AUTOSAR XML (schema 4.0)
standard types defined: float32, float64, sint16, sint32, sint8, uint16, uint32, uint8, void, boolean
package /ImplDataTypes
  7 x impl type, all with category=TYPE_REFERENCE, type-emitter=RTE:
    IoPositionSensorReadingType: implementation-data-type=uint8
    IoWeightSensorReadingType: implementation-data-type=uint16
    MultiStateBtn: implementation-data-type=uint8
    SeatModeBtnType: implementation-data-type=uint8
    SensorPositionType: implementation-data-type=uint8
    SensorWeightType: implementation-data-type=uint8
    StepMotorStepType: implementation-data-type=uint8
package /MappingSets
  data type mapping set MappingSet: mode-request-type-map{implementation-data-type=uint8, mode-group=SeatCtrlMode}
package /PortInterfaces/ClientServer
  6 x client server interface:
    CsIf_IoGetSensorPosition
      operation IoGet
        arg position: type=IoPositionSensorReadingType, direction=OUT
    CsIf_IoGetSensorWeight
      operation IoGet
        arg weight: type=IoWeightSensorReadingType, direction=OUT
    CsIf_IoSetMotor
      operation IoSetForward
      operation IoSetReverse
    CsIf_PositionSensor
      operation GetPosition
        arg position: type=SensorPositionType, direction=OUT
    CsIf_StepMotor
      operation Move
        arg step: type=StepMotorStepType, direction=IN
    CsIf_WeightSensor
      operation GetWeight
        arg weight: type=SensorWeightType, direction=OUT
package /PortInterfaces/ModeSwitch
  mode switch interface MsIf_SeatCtrlMode
    mode group SeatCtrlMode: type=SeatCtrlMode
  mode declaration group SeatCtrlMode: category=ALPHABETIC_ORDER, initial-mode=INIT, on-transition-value=255
    mode AUTO
    mode INIT
    mode MANUAL
package /PortInterfaces/SenderReceiver
  sender receiver interface SrIf_SeatCntlData
    data Height: type=uint8
    data Incline: type=uint8
    data Slide: type=uint8
  sender receiver interface SrIf_SeatCtrlBtns
    data HeightBtnState: type=MultiStateBtn
    data InclineBtnState: type=MultiStateBtn
    data SlideBtnState: type=MultiStateBtn
  sender receiver interface SrIf_SeatModeBtn
    data SeatModeBtn: type=SeatModeBtnType
package /SoftwareComponents
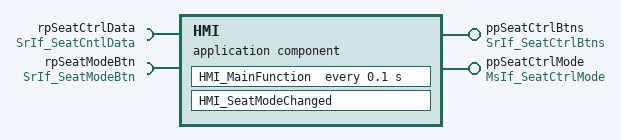
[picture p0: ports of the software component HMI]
  application sw component type HMI
    provide port ppSeatCtrlBtns: provided-interface=SrIf_SeatCtrlBtns
    provide port ppSeatCtrlMode: provided-interface=MsIf_SeatCtrlMode
    require port rpSeatCtrlData: required-interface=SrIf_SeatCntlData
    require port rpSeatModeBtn: required-interface=SrIf_SeatModeBtn
    behavior Ibhv_HMI: data-type-mapping=MappingSet, handle-termination-and-restart=NO-SUPPORT
      data received event DRE_rpSeatModeBtn_SeatModeBtn: start-on-event=HMI_SeatModeChanged, data=rpSeatModeBtn.SeatModeBtn
      timing event TE_HMI_MainFunction_100ms: start-on-event=HMI_MainFunction, period=0.1
      runnable HMI_MainFunction
        data-receive-point-by-arguments:
          access DRP_rpSeatCtrlData_Height: accessed-variable=rpSeatCtrlData.Height
          access DRP_rpSeatCtrlData_Incline: accessed-variable=rpSeatCtrlData.Incline
          access DRP_rpSeatCtrlData_Slide: accessed-variable=rpSeatCtrlData.Slide
        data-send-points:
          access DSP_ppSeatCtrlBtns_HeightBtnState: accessed-variable=ppSeatCtrlBtns.HeightBtnState
          access DSP_ppSeatCtrlBtns_InclineBtnState: accessed-variable=ppSeatCtrlBtns.InclineBtnState
          access DSP_ppSeatCtrlBtns_SlideBtnState: accessed-variable=ppSeatCtrlBtns.SlideBtnState
      runnable HMI_SeatModeChanged
        data-receive-point-by-arguments:
          access DRP_rpSeatModeBtn_SeatModeBtn: accessed-variable=rpSeatModeBtn.SeatModeBtn
        mode switch point MSP_ppSeatCtrlMode_ppSeatCtrlMode: mode-group=ppSeatCtrlMode.SeatCtrlMode
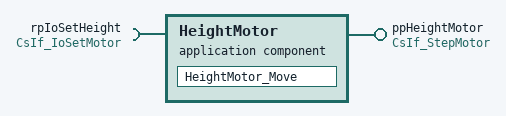
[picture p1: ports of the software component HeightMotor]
  application sw component type HeightMotor
    provide port ppHeightMotor: provided-interface=CsIf_StepMotor
    require port rpIoSetHeight: required-interface=CsIf_IoSetMotor
    behavior Ibhv_HeightMotor: data-type-mapping=MappingSet, handle-termination-and-restart=NO-SUPPORT
      operation invoked event OIE_ppHeightMotor_Move: start-on-event=HeightMotor_Move, operation=ppHeightMotor.Move
      runnable HeightMotor_Move
        sync call SCP_rpIoSetHeight_IoSetForward: operation=rpIoSetHeight.IoSetForward, timeout=0.0
        sync call SCP_rpIoSetHeight_IoSetReverse: operation=rpIoSetHeight.IoSetReverse, timeout=0.0
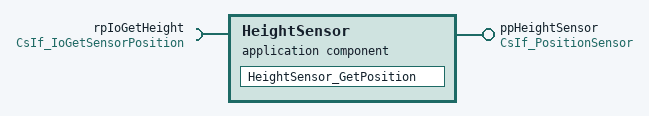
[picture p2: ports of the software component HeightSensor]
  application sw component type HeightSensor
    provide port ppHeightSensor: provided-interface=CsIf_PositionSensor
    require port rpIoGetHeight: required-interface=CsIf_IoGetSensorPosition
    behavior Ibhv_HeightSensor: data-type-mapping=MappingSet, handle-termination-and-restart=NO-SUPPORT
      operation invoked event OIE_ppHeightSensor_GetPosition: start-on-event=HeightSensor_GetPosition, operation=ppHeightSensor.GetPosition
      runnable HeightSensor_GetPosition
        sync call SCP_rpIoGetHeight_IoGet: operation=rpIoGetHeight.IoGet, timeout=0.0
  10 x swc implementation, all with programming-language=C, sw-version=1.0.0, vendor-id=255:
    Impl_HMI: behavior=Ibhv_HMI
      code-descriptors:
        code Code: artifact-descriptors=autosar-engineering-object={short-label=SWC.c, category=SWSRC}
      resource consumption ResourceConsumption
    Impl_HeightMotor: behavior=Ibhv_HeightMotor
      code-descriptors:
        code Code: artifact-descriptors=autosar-engineering-object={short-label=SWC.c, category=SWSRC}
      resource consumption ResourceConsumption
    Impl_HeightSensor: behavior=Ibhv_HeightSensor
      code-descriptors:
        code Code: artifact-descriptors=autosar-engineering-object={short-label=SWC.c, category=SWSRC}
      resource consumption ResourceConsumption
    Impl_InclineMotor: behavior=Ibhv_InclineMotor
      code-descriptors:
        code Code: artifact-descriptors=autosar-engineering-object={short-label=SWC.c, category=SWSRC}
      resource consumption ResourceConsumption
    Impl_InclineSensor: behavior=Ibhv_InclineSensor
      code-descriptors:
        code Code: artifact-descriptors=autosar-engineering-object={short-label=SWC.c, category=SWSRC}
      resource consumption ResourceConsumption
    Impl_IoHwAbs: behavior=Ibhv_IoHwAbs
      code-descriptors:
        code Code: artifact-descriptors=autosar-engineering-object={short-label=SWC.c, category=SWSRC}
      resource consumption ResourceConsumption
    Impl_SeatMrg: behavior=Ibhv_SeatMrg
      code-descriptors:
        code Code: artifact-descriptors=autosar-engineering-object={short-label=SWC.c, category=SWSRC}
      resource consumption ResourceConsumption
    Impl_SideSensor: behavior=Ibhv_SideSensor
      code-descriptors:
        code Code: artifact-descriptors=autosar-engineering-object={short-label=SWC.c, category=SWSRC}
      resource consumption ResourceConsumption
    Impl_SlideMotor: behavior=Ibhv_SlideMotor
      code-descriptors:
        code Code: artifact-descriptors=autosar-engineering-object={short-label=SWC.c, category=SWSRC}
      resource consumption ResourceConsumption
    Impl_WeightSensor: behavior=Ibhv_WeightSensor
      code-descriptors:
        code Code: artifact-descriptors=autosar-engineering-object={short-label=SWC.c, category=SWSRC}
      resource consumption ResourceConsumption
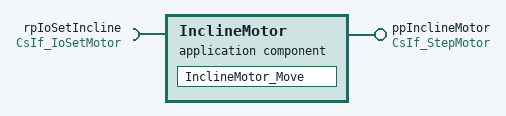
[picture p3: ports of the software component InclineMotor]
  application sw component type InclineMotor
    provide port ppInclineMotor: provided-interface=CsIf_StepMotor
    require port rpIoSetIncline: required-interface=CsIf_IoSetMotor
    behavior Ibhv_InclineMotor: data-type-mapping=MappingSet, handle-termination-and-restart=NO-SUPPORT
      operation invoked event OIE_ppInclineMotor_Move: start-on-event=InclineMotor_Move, operation=ppInclineMotor.Move
      runnable InclineMotor_Move
        sync call SCP_rpIoSetIncline_IoSetForward: operation=rpIoSetIncline.IoSetForward, timeout=0.0
        sync call SCP_rpIoSetIncline_IoSetReverse: operation=rpIoSetIncline.IoSetReverse, timeout=0.0
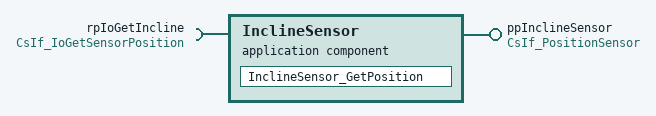
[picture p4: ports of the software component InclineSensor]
  application sw component type InclineSensor
    provide port ppInclineSensor: provided-interface=CsIf_PositionSensor
    require port rpIoGetIncline: required-interface=CsIf_IoGetSensorPosition
    behavior Ibhv_InclineSensor: data-type-mapping=MappingSet, handle-termination-and-restart=NO-SUPPORT
      operation invoked event OIE_ppInclineSensor_GetPosition: start-on-event=InclineSensor_GetPosition, operation=ppInclineSensor.GetPosition
      runnable InclineSensor_GetPosition
        sync call SCP_rpIoGetIncline_IoGet: operation=rpIoGetIncline.IoGet, timeout=0.0
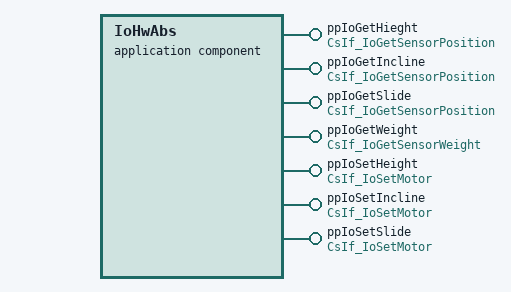
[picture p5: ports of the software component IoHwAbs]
  application sw component type IoHwAbs
    7 x provide port:
      ppIoGetHieght: provided-interface=CsIf_IoGetSensorPosition
      ppIoGetIncline: provided-interface=CsIf_IoGetSensorPosition
      ppIoGetSlide: provided-interface=CsIf_IoGetSensorPosition
      ppIoGetWeight: provided-interface=CsIf_IoGetSensorWeight
      ppIoSetHeight: provided-interface=CsIf_IoSetMotor
      ppIoSetIncline: provided-interface=CsIf_IoSetMotor
      ppIoSetSlide: provided-interface=CsIf_IoSetMotor
    behavior Ibhv_IoHwAbs: data-type-mapping=MappingSet, handle-termination-and-restart=NO-SUPPORT
      10 x operation invoked event:
        OIE_ppIoGetHieght_IoGet: start-on-event=IoHwAbs_ECUGet_Height, operation=ppIoGetHieght.IoGet
        OIE_ppIoGetIncline_IoGet: start-on-event=IoHwAbs_ECUGet_Incline, operation=ppIoGetIncline.IoGet
        OIE_ppIoGetSlide_IoGet: start-on-event=IoHwAbs_ECUGet_Slide, operation=ppIoGetSlide.IoGet
        OIE_ppIoGetWeight_IoGet: start-on-event=IoHwAbs_ECUGet_Weight, operation=ppIoGetWeight.IoGet
        OIE_ppIoSetHeight_IoSetForward: start-on-event=IoHwAbs_ECUSetForward_Height, operation=ppIoSetHeight.IoSetForward
        OIE_ppIoSetHeight_IoSetReverse: start-on-event=IoHwAbs_ECUSetReverse_Height, operation=ppIoSetHeight.IoSetReverse
        OIE_ppIoSetIncline_IoSetForward: start-on-event=IoHwAbs_ECUSetForward_Incline, operation=ppIoSetIncline.IoSetForward
        OIE_ppIoSetIncline_IoSetReverse: start-on-event=IoHwAbs_ECUSetReverse_Incline, operation=ppIoSetIncline.IoSetReverse
        OIE_ppIoSetSlide_IoSetForward: start-on-event=IoHwAbs_ECUSetForward_Slide, operation=ppIoSetSlide.IoSetForward
        OIE_ppIoSetSlide_IoSetReverse: start-on-event=IoHwAbs_ECUSetReverse_Slide, operation=ppIoSetSlide.IoSetReverse
      10 x runnable:
        IoHwAbs_ECUGet_Height
        IoHwAbs_ECUGet_Incline
        IoHwAbs_ECUGet_Slide
        IoHwAbs_ECUGet_Weight
        IoHwAbs_ECUSetForward_Height
        IoHwAbs_ECUSetForward_Incline
        IoHwAbs_ECUSetForward_Slide
        IoHwAbs_ECUSetReverse_Height
        IoHwAbs_ECUSetReverse_Incline
        IoHwAbs_ECUSetReverse_Slide
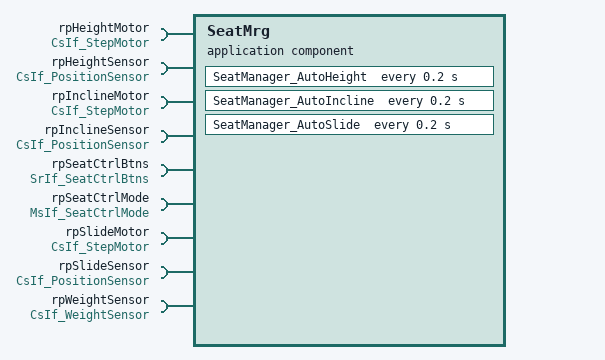
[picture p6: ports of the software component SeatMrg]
  application sw component type SeatMrg
    9 x require port:
      rpHeightMotor: required-interface=CsIf_StepMotor
      rpHeightSensor: required-interface=CsIf_PositionSensor
      rpInclineMotor: required-interface=CsIf_StepMotor
      rpInclineSensor: required-interface=CsIf_PositionSensor
      rpSeatCtrlBtns: required-interface=SrIf_SeatCtrlBtns
      rpSeatCtrlMode: required-interface=MsIf_SeatCtrlMode
      rpSlideMotor: required-interface=CsIf_StepMotor
      rpSlideSensor: required-interface=CsIf_PositionSensor
      rpWeightSensor: required-interface=CsIf_WeightSensor
    behavior Ibhv_SeatMrg: data-type-mapping=MappingSet, handle-termination-and-restart=NO-SUPPORT
      data received event DRE_rpSeatCtrlBtns_HeightBtnState: start-on-event=SeatManager_SetHeight, data=rpSeatCtrlBtns.HeightBtnState
      data received event DRE_rpSeatCtrlBtns_InclineBtnState: start-on-event=SeatManager_SetIncline, data=rpSeatCtrlBtns.InclineBtnState
      data received event DRE_rpSeatCtrlBtns_SlideBtnState: start-on-event=SeatManager_SetSlide, data=rpSeatCtrlBtns.SlideBtnState
      timing event TE_SeatManager_AutoHeight_200ms: start-on-event=SeatManager_AutoHeight, period=0.2
      timing event TE_SeatManager_AutoIncline_200ms: start-on-event=SeatManager_AutoIncline, period=0.2
      timing event TE_SeatManager_AutoSlide_200ms: start-on-event=SeatManager_AutoSlide, period=0.2
      6 x runnable:
        SeatManager_AutoHeight
          sync call SCP_rpHeightMotor_Move: operation=rpHeightMotor.Move, timeout=0.0
          sync call SCP_rpHeightSensor_GetPosition: operation=rpHeightSensor.GetPosition, timeout=0.0
          sync call SCP_rpWeightSensor_GetWeight: operation=rpWeightSensor.GetWeight, timeout=0.0
        SeatManager_AutoIncline
          sync call SCP_rpInclineMotor_Move: operation=rpInclineMotor.Move, timeout=0.0
          sync call SCP_rpInclineSensor_GetPosition: operation=rpInclineSensor.GetPosition, timeout=0.0
          sync call SCP_rpWeightSensor_GetWeight: operation=rpWeightSensor.GetWeight, timeout=0.0
        SeatManager_AutoSlide
          sync call SCP_rpSlideMotor_Move: operation=rpSlideMotor.Move, timeout=0.0
          sync call SCP_rpSlideSensor_GetPosition: operation=rpSlideSensor.GetPosition, timeout=0.0
          sync call SCP_rpWeightSensor_GetWeight: operation=rpWeightSensor.GetWeight, timeout=0.0
        SeatManager_SetHeight
          data-receive-point-by-arguments:
            access DRP_rpSeatCtrlBtns_HeightBtnState: accessed-variable=rpSeatCtrlBtns.HeightBtnState
          sync call SCP_rpHeightMotor_Move: operation=rpHeightMotor.Move, timeout=0.0
        SeatManager_SetIncline
          data-receive-point-by-arguments:
            access DRP_rpSeatCtrlBtns_InclineBtnState: accessed-variable=rpSeatCtrlBtns.InclineBtnState
          sync call SCP_rpSlideMotor_Move: operation=rpSlideMotor.Move, timeout=0.0
        SeatManager_SetSlide
          data-receive-point-by-arguments:
            access DRP_rpSeatCtrlBtns_SlideBtnState: accessed-variable=rpSeatCtrlBtns.SlideBtnState
          sync call SCP_rpInclineMotor_Move: operation=rpInclineMotor.Move, timeout=0.0
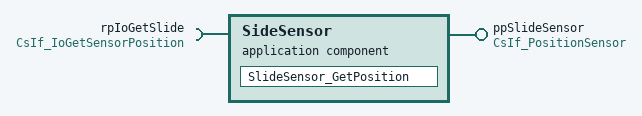
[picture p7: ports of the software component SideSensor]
  application sw component type SideSensor
    provide port ppSlideSensor: provided-interface=CsIf_PositionSensor
    require port rpIoGetSlide: required-interface=CsIf_IoGetSensorPosition
    behavior Ibhv_SideSensor: data-type-mapping=MappingSet, handle-termination-and-restart=NO-SUPPORT
      operation invoked event OIE_ppSlideSensor_GetPosition: start-on-event=SlideSensor_GetPosition, operation=ppSlideSensor.GetPosition
      runnable SlideSensor_GetPosition
        sync call SCP_rpIoGetSlide_IoGet: operation=rpIoGetSlide.IoGet, timeout=0.0
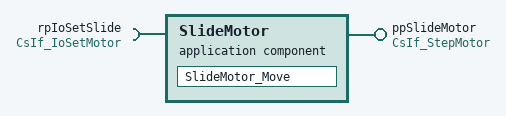
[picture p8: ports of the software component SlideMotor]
  application sw component type SlideMotor
    provide port ppSlideMotor: provided-interface=CsIf_StepMotor
    require port rpIoSetSlide: required-interface=CsIf_IoSetMotor
    behavior Ibhv_SlideMotor: data-type-mapping=MappingSet, handle-termination-and-restart=NO-SUPPORT
      operation invoked event OIE_ppSlideMotor_Move: start-on-event=SlideMotor_Move, operation=ppSlideMotor.Move
      runnable SlideMotor_Move
        sync call SCP_rpIoSetSlide_IoSetForward: operation=rpIoSetSlide.IoSetForward, timeout=0.0
        sync call SCP_rpIoSetSlide_IoSetReverse: operation=rpIoSetSlide.IoSetReverse, timeout=0.0
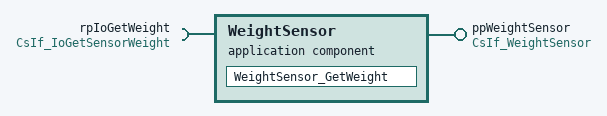
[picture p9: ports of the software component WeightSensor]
  application sw component type WeightSensor
    provide port ppWeightSensor: provided-interface=CsIf_WeightSensor
    require port rpIoGetWeight: required-interface=CsIf_IoGetSensorWeight
    behavior Ibhv_WeightSensor: data-type-mapping=MappingSet, handle-termination-and-restart=NO-SUPPORT
      operation invoked event OIE_ppWeightSensor_GetWeight: start-on-event=WeightSensor_GetWeight, operation=ppWeightSensor.GetWeight
      runnable WeightSensor_GetWeight
        sync call SCP_rpIoGetWeight_IoGet: operation=rpIoGetWeight.IoGet, timeout=0.0
package /Compositions
  composition sw component type Seat_App_MainComposition
    10 x component:
      HMI: type=HMI
      HeightMotor: type=HeightMotor
      HeightSensor: type=HeightSensor
      InclineMotor: type=InclineMotor
      InclineSensor: type=InclineSensor
      IoHwAbs: type=IoHwAbs
      SeatMrg: type=SeatMrg
      SideSensor: type=SideSensor
      SlideMotor: type=SlideMotor
      WeightSensor: type=WeightSensor
    connect HMI.ppSeatCtrlMode -> SeatMrg.rpSeatCtrlMode
    connect HeightMotor.ppHeightMotor -> SeatMrg.rpHeightMotor
    connect HeightSensor.ppHeightSensor -> SeatMrg.rpHeightSensor
    connect InclineMotor.ppInclineMotor -> SeatMrg.rpInclineMotor
    connect InclineSensor.ppInclineSensor -> SeatMrg.rpInclineSensor
    connect IoHwAbs.ppIoGetHieght -> HeightSensor.rpIoGetHeight
    connect IoHwAbs.ppIoGetIncline -> InclineSensor.rpIoGetIncline
    connect IoHwAbs.ppIoGetSlide -> SideSensor.rpIoGetSlide
    connect IoHwAbs.ppIoGetWeight -> WeightSensor.rpIoGetWeight
    connect IoHwAbs.ppIoSetHeight -> HeightMotor.rpIoSetHeight
    connect IoHwAbs.ppIoSetIncline -> InclineMotor.rpIoSetIncline
    connect IoHwAbs.ppIoSetSlide -> SlideMotor.rpIoSetSlide
    connect SideSensor.ppSlideSensor -> SeatMrg.rpSlideSensor
    connect SlideMotor.ppSlideMotor -> SeatMrg.rpSlideMotor
    connect WeightSensor.ppWeightSensor -> SeatMrg.rpWeightSensor
    connect HMI.ppSeatCtrlBtns -> SeatMrg.rpSeatCtrlBtns
